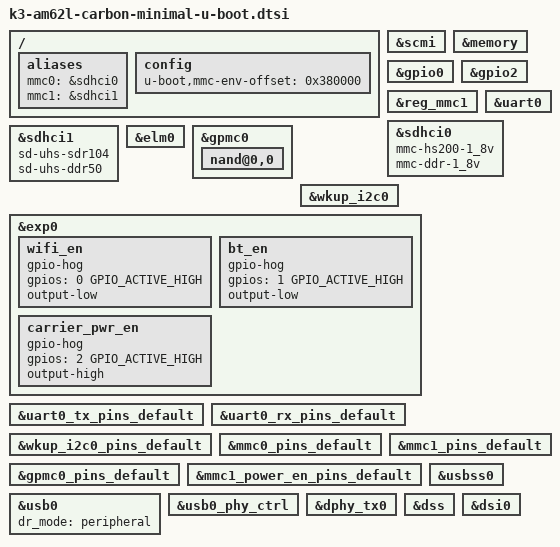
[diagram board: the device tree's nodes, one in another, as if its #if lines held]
// SPDX-License-Identifier: GPL-2.0-only or MIT
/*
 * Copyright (C) 2026 Ezurio LLC
 */

#include "k3-am62l-carbon-binman.dtsi"

/ {
	aliases {
		mmc0 = &sdhci0;
		mmc1 = &sdhci1;
	};

	config {
		u-boot,mmc-env-offset = <0x380000>;
	};
};

&scmi {
	bootph-all;
};

&memory {
	bootph-all;
};

&gpio0 {
	bootph-all;
};

&gpio2 {
	bootph-all;
};

&reg_mmc1 {
	bootph-all;
};

&uart0 {
	bootph-all;
};

&sdhci0 {
	bootph-all;
	mmc-hs200-1_8v;
	mmc-ddr-1_8v;
};

&sdhci1 {
	bootph-all;
	sd-uhs-sdr104;
	sd-uhs-ddr50;
};

&elm0 {
	bootph-all;
};

&gpmc0 {
	bootph-all;

	nand@0,0 {
		bootph-all;
	};
};

&wkup_i2c0 {
	bootph-all;
};

&exp0 {
	bootph-all;

	wifi_en {
		bootph-all;
		gpio-hog;
		gpios = <0 GPIO_ACTIVE_HIGH>;
		output-low;
	};

	bt_en {
		bootph-all;
		gpio-hog;
		gpios = <1 GPIO_ACTIVE_HIGH>;
		output-low;
	};

	carrier_pwr_en {
		bootph-all;
		gpio-hog;
		gpios = <2 GPIO_ACTIVE_HIGH>;
		output-high;
	};
};

&uart0_tx_pins_default {
	bootph-all;
};

&uart0_rx_pins_default {
	bootph-all;
};

&wkup_i2c0_pins_default {
	bootph-all;
};

&mmc0_pins_default {
	bootph-all;
};

&mmc1_pins_default {
	bootph-all;
};

&gpmc0_pins_default {
	bootph-all;
};

&mmc1_power_en_pins_default {
	bootph-all;
};

#ifdef CONFIG_SPL_DFU
/* Required for USB DFU Boot */
&usbss0 {
	bootph-all;
};

&usb0 {
	dr_mode = "peripheral";
	bootph-all;
};

&usb0_phy_ctrl {
	bootph-all;
};
#endif

&dphy_tx0 {
	/delete-property/ bootph-all;
};

&dss {
	/delete-property/ bootph-all;
};

&dsi0 {
	/delete-property/ bootph-all;
};
